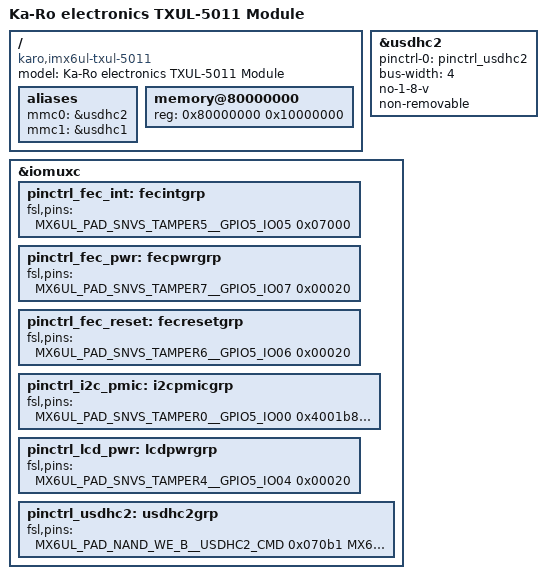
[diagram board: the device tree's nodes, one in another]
// SPDX-License-Identifier: GPL-2.0+
/*
 * Copyright (C) 2026 Ka-Ro Electronics GmbH
 * Ka-Ro TXUL-5011 module (i.MX6UL)
 */

/dts-v1/;

#include "imx6ul.dtsi"
#include <dt-bindings/gpio/gpio.h>
#include "imx6ul-txul.dtsi"

/ {
	model = "Ka-Ro electronics TXUL-5011 Module";
	compatible = "karo,imx6ul-txul-5011", "fsl,imx6ul";

	/* imx8mp-karo.dtsi: the eMMC is mmc0 in the module DT */
	aliases {
		mmc0 = &usdhc2;
		mmc1 = &usdhc1;
	};

	memory@80000000 {
		device_type = "memory";
		reg = <0x80000000 0x10000000>;	/* 256 MiB DDR3 */
	};
};

&usdhc2 {
	pinctrl-names = "default";
	pinctrl-0 = <&pinctrl_usdhc2>;
	bus-width = <4>;
	no-1-8-v;
	non-removable;
	status = "okay";
};

&iomuxc {
	pinctrl_fec_int: fecintgrp {
		fsl,pins = <
			MX6UL_PAD_SNVS_TAMPER5__GPIO5_IO05	0x07000
		>;
	};

	pinctrl_fec_pwr: fecpwrgrp {
		fsl,pins = <
			MX6UL_PAD_SNVS_TAMPER7__GPIO5_IO07	0x00020
		>;
	};

	pinctrl_fec_reset: fecresetgrp {
		fsl,pins = <
			MX6UL_PAD_SNVS_TAMPER6__GPIO5_IO06	0x00020
		>;
	};

	pinctrl_i2c_pmic: i2cpmicgrp {
		fsl,pins = <
			MX6UL_PAD_SNVS_TAMPER0__GPIO5_IO00	0x4001b8b1
			MX6UL_PAD_SNVS_TAMPER1__GPIO5_IO01	0x4001b8b1
		>;
	};

	pinctrl_lcd_pwr: lcdpwrgrp {
		fsl,pins = <
			MX6UL_PAD_SNVS_TAMPER4__GPIO5_IO04	0x00020
		>;
	};

	pinctrl_usdhc2: usdhc2grp {
		fsl,pins = <
			MX6UL_PAD_NAND_WE_B__USDHC2_CMD		0x070b1
			MX6UL_PAD_NAND_RE_B__USDHC2_CLK		0x070b1
			MX6UL_PAD_NAND_DATA00__USDHC2_DATA0	0x070b1
			MX6UL_PAD_NAND_DATA01__USDHC2_DATA1	0x070b1
			MX6UL_PAD_NAND_DATA02__USDHC2_DATA2	0x070b1
			MX6UL_PAD_NAND_DATA03__USDHC2_DATA3	0x070b1
			/* eMMC HW reset */
			MX6UL_PAD_NAND_ALE__USDHC2_RESET_B	0x170b0
		>;
	};
};
